# M3351 register map
File version: 1.0
Registers are 32-bit, read-write, reset 0x0 unless marked. A register's access mark holds for its fields unless they carry their own. Offsets are from the block's base; [hi:lo] are bit positions.

## SCS — SYST_SCR Register Map
Base 0xE000E000
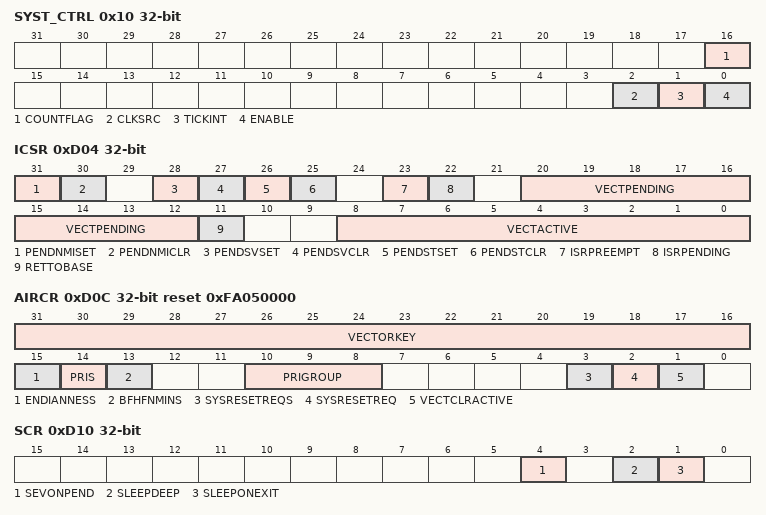
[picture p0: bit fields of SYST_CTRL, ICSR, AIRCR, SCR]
0x10 SYST_CTRL — SysTick Control and Status Register
  [16] COUNTFLAG — System Tick Counter Flag. Returns 1 if timer counted to 0 since last time this register was read. COUNTFLAG is set by a count transition from 1 to 0. COUNTFLAG is cleared on read or by a write to the Current Value register.
  [2] CLKSRC — System Tick Clock Source Selection
    0=Clock source is the (optional) external reference clock; 1=Core clock used for SysTick
  [1] TICKINT — System Tick Interrupt Enabled
    0=Counting down to 0 does not cause the SysTick exception to be pended. Software can use COUNTFLAG to determine if a count to zero has occurred; 1=Counting down to 0 will cause the SysTick exception to be pended. Clearing the SysTick current value register by a register write in software will not cause SysTick to be pended
  [0] ENABLE — System Tick Counter Enabled
    0=Counter Disabled; 1=Counter will operate in a multi-shot manner
0x14 SYST_LOAD reset not defined — SysTick Reload Value Register
  [23:0] RELOAD — System Tick Reload Value. Value to load into the Current Value register when the counter reaches 0.
0x18 SYST_VAL reset not defined — SysTick Current Value Register
  [23:0] CURRENT — System Tick Current Value. Current counter value. This is the value of the counter at the time it is sampled. The counter does not provide read-modify-Write Protect. The register is write-clear. A software write of any value will clear the register to 0.
0xD04 ICSR — Interrupt Control and State Register
  [31] PENDNMISET — NMI Set-pending Bit. Write Operation: Note: Because NMI is the highest-priority exception, normally the processor enters the NMI exception handler as soon as it detects a write of 1 to this bit. Entering the handler then clears this bit to 0. This means a read of this bit by the NMI exception handler returns 1 only if the NMI signal is reasserted while the processor is executing that handler.
    0=No effect. NMI exception is not pending; 1=Change NMI exception state to pending. NMI exception is pending
  [30] PENDNMICLR — Pend NMI clear Bit. Write Operation: Note: This bit is write-one-to-clear. Writes of zero are ignored.
    0=No effect; 1=Clear pending status
  [28] PENDSVSET — PendSV Set-pending Bit. Write Operation: Note: Writing 1 to this bit is the only way to set the PendSV exception state to pending.
    0=No effect. PendSV exception is not pending; 1=Change PendSV exception state to pending. PendSV exception is pending
  [27] PENDSVCLR — PendSV Clear-pending Bit (Write Only). Write Operation: Note: This is a write only bit. To clear the PENDSV bit, you must 'write 0 to PENDSVSET and write 1 to PENDSVCLR' at the same time.
    0=No effect; 1=Remove the pending state from the PendSV exception
  [26] PENDSTSET — SysTick Exception Set-pending Bit. Write Operation:
    0=No effect. SysTick exception is not pending; 1=Change SysTick exception state to pending. SysTick exception is pending
  [25] PENDSTCLR — SysTick Exception Clear-pending Bit (Write Only). Write Operation: Note: This is a write only bit. To clear the PENDST bit, you must 'write 0 to PENDSTSET and write 1 to PENDSTCLR' at the same time.
    0=No effect; 1=Remove the pending state from the SysTick exception
  [23] ISRPREEMPT — Interrupt Preempt Bit (Read Only). If set, a pending exception will be serviced on exit from the debug halt state.
    0=Pending exception is not handled on exit from debug state; 1=Pending exception is handled on exit from debug state
  [22] ISRPENDING — Interrupt Pending Flag, Excluding NMI and Faults (Read Only)
    0=Interrupt not pending; 1=Interrupt pending
  [20:12] VECTPENDING — Number of the Highest Pended Exception. Indicate the Exception Number of the Highest Priority Pending Enabled Exception. The value indicated by this field includes the effect of the BASEPRI and FAULTMASK registers, but not any effect of the PRIMASK register.
    0=No pending exceptions
  [11] RETTOBASE — Preempted Active Exceptions Indicator. Indicate whether There are Preempted Active Exceptions.
    0=There are preempted active exceptions to execute; 1=There are no active exceptions, or the currently-executing exception is the only active exception
  [8:0] VECTACTIVE — Number of the Current Active Exception
    0=Thread mode
0xD08 VTOR — Vector Table Offset Register
  [31:9] TBLOFF — Table Offset Bits. The vector table address for the selected Security state.
0xD0C AIRCR reset 0xFA050000 — Application Interrupt and Reset Control Register
  [31:16] VECTORKEY — Register Access Key. When writing this register, this field should be 0x05FA, otherwise the write action will be unpredictable. The VECTORKEY filed is used to prevent accidental write to this register from resetting the system or clearing of the exception status.
  [15] ENDIANNESS — Data Endianness
    0=Little-endian; 1=Big-endian
  [14] PRIS — Prioritize Secure exceptions. The value of this bit defines whether Secure exception priority boosting is enabled.
    0=Priority ranges of Secure and Non-secure exceptions are identical; 1=Non-secure exceptions are de-prioritized
  [13] BFHFNMINS — BusFault, HardFault, and NMI Non-secure enable. The value of this bit defines whether BusFault and NMI exceptions are Non-secure, and whether exceptions target the Non-secure HardFault exception.
    0=BusFault, HardFault, and NMI are Secure; 1=BusFault and NMI are Non-secure and exceptions can target Non-secure HardFault
  [10:8] PRIGROUP — Interrupt Priority Grouping. This field determines the Split Of Group priority from subpriority,
  [3] SYSRESETREQS — System reset request, Secure state only. The value of this bit defines whether the SYSRESETREQ bit is functional for Non-secure use.
    0=SYSRESETREQ functionality is available to both Security states; 1=SYSRESETREQ functionality is only available to Secure state
  [2] SYSRESETREQ — System Reset Request (Write Only). Writing this bit to 1 will cause a reset signal to be asserted to the chip and indicate a reset is requested. This bit is write only and self-cleared as part of the reset sequence.
  [1] VECTCLRACTIVE — Exception Active Status Clear Bit (Write Only). Setting this bit to 1 will clear all active state information for fixed and configurable exceptions. This bit is write only and can only be written when the core is halted. Note: It is the debugger's responsibility to re-initialize the stack.
0xD10 SCR — System Control Register
  [4] SEVONPEND — Send Event on Pending. When an event or interrupt enters pending state, the event signal wakes up the processor from WFE. If the processor is not waiting for an event, the event is registered and affects the next WFE. The processor also wakes up on execution of an SEV instruction or an external event.
    0=Only enabled interrupts or events can wake up the processor, while disabled interrupts are excluded; 1=Enabled events and all interrupts, including disabled interrupts, can wake up the processor
  [2] SLEEPDEEP — Processor Deep Sleep and Sleep Mode Selection. Control whether the Processor Uses Sleep Or Deep Sleep as its Low Power Mode.
    0=Sleep; 1=Deep sleep
  [1] SLEEPONEXIT — Sleep-on-exit Enable Control. This bit indicates Sleep-On-Exit when Returning from Handler Mode to Thread Mode. Set this bit to 1 enable an interrupt driven application to avoid returning to an empty main application.
    0=Do not sleep when returning to Thread mode; 1=Enter sleep, or deep sleep, on return from an ISR to Thread mode
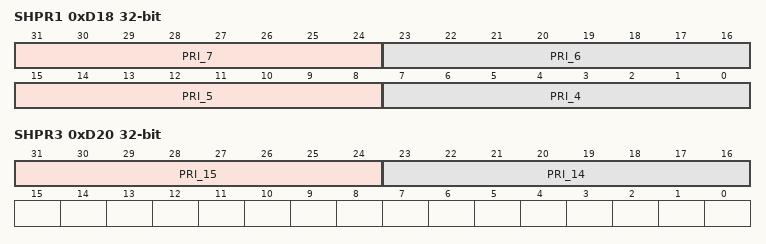
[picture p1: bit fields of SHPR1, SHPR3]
0xD18 SHPR1 — System Handler Priority Register 1
  [31:24] PRI_7 — Priority of system handler 7
  [23:16] PRI_6 — Priority of system handler 6, UsageFault
  [15:8] PRI_5 — Priority of system handler 5, BusFault
  [7:0] PRI_4 — Priority of system handler 4, MemManage
0xD1C SHPR2 — System Handler Priority Register 2
  [31:24] PRI_11 — Priority of System Handler 11 - SVCall '0' denotes the highest priority and '15' denotes the lowest priority.
0xD20 SHPR3 — System Handler Priority Register 3
  [31:24] PRI_15 — Priority of System Handler 15 - SysTick '0' denotes the highest priority and '15' denotes the lowest priority.
  [23:16] PRI_14 — Priority of System Handler 14 - PendSV '0' denotes the highest priority and '15' denotes the lowest priority.
